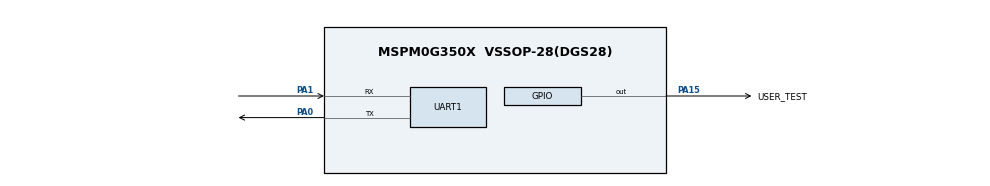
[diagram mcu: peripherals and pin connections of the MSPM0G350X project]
/**
 * @cliArgs --device "MSPM0G350X" --package "VSSOP-28(DGS28)" --part "Default" --product "mspm0_sdk@1.30.00.03"
 * @versions {"tool":"1.19.0+3426"}
 */

/**
 * Import the modules used in this configuration.
 */
const GPIO          = scripting.addModule("/ti/driverlib/GPIO", {}, false);
const GPIO1         = GPIO.addInstance();
const SYSCTL        = scripting.addModule("/ti/driverlib/SYSCTL");
const TIMER         = scripting.addModule("/ti/driverlib/TIMER", {}, false);
const TIMER1        = TIMER.addInstance();
const UART          = scripting.addModule("/ti/driverlib/UART", {}, false);
const UART1         = UART.addInstance();
const ProjectConfig = scripting.addModule("/ti/project_config/ProjectConfig");

/**
 * Write custom configuration values to the imported modules.
 */
const divider6       = system.clockTree["PLL_CLK2X_DIV"];
divider6.divideValue = 4;

const divider7       = system.clockTree["PLL_PDIV"];
divider7.divideValue = 2;

const divider9       = system.clockTree["UDIV"];
divider9.divideValue = 2;

const multiplier2         = system.clockTree["PLL_QDIV"];
multiplier2.multiplyValue = 10;

const mux8       = system.clockTree["HSCLKMUX"];
mux8.inputSelect = "HSCLKMUX_SYSPLL2X";

GPIO1.$name                         = "GPIO_LEDS";
GPIO1.port                          = "PORTA";
GPIO1.associatedPins[0].$name       = "USER_TEST";
GPIO1.associatedPins[0].pin.$assign = "PA15";

const Board = scripting.addModule("/ti/driverlib/Board", {}, false);

SYSCTL.forceDefaultClkConfig = true;
SYSCTL.clockTreeEn           = true;

TIMER1.timerStartTimer  = true;
TIMER1.$name            = "SWTIMER";
TIMER1.timerClkDiv      = 8;
TIMER1.timerPeriod      = "1.0";
TIMER1.timerClkPrescale = 256;
TIMER1.timerMode        = "PERIODIC";

UART1.$name                            = "DEBUG_SCI";
UART1.targetBaudRate                   = 115200;
UART1.parity                           = "EVEN";
UART1.enableFIFO                       = true;
UART1.peripheral.$assign               = "UART0";
UART1.peripheral.rxPin.$assign         = "PA1";
UART1.peripheral.txPin.$assign         = "PA0";
UART1.txPinConfig.$name                = "ti_driverlib_gpio_GPIOPinGeneric0";
UART1.txPinConfig.direction            = scripting.forceWrite("OUTPUT");
UART1.txPinConfig.hideOutputInversion  = scripting.forceWrite(false);
UART1.txPinConfig.onlyInternalResistor = scripting.forceWrite(false);
UART1.txPinConfig.passedPeripheralType = scripting.forceWrite("Digital");
UART1.rxPinConfig.$name                = "ti_driverlib_gpio_GPIOPinGeneric1";
UART1.rxPinConfig.hideOutputInversion  = scripting.forceWrite(false);
UART1.rxPinConfig.onlyInternalResistor = scripting.forceWrite(false);
UART1.rxPinConfig.passedPeripheralType = scripting.forceWrite("Digital");

ProjectConfig.deviceSpin = "MSPM0G3507";
scripting.suppress("Migrating requires going through the Switch Board or Device menu in the Device View section\\.", ProjectConfig, "deviceSpin");

/**
 * Pinmux solution for unlocked pins/peripherals. This ensures that minor changes to the automatic solver in a future
 * version of the tool will not impact the pinmux you originally saw.  These lines can be completely deleted in order to
 * re-solve from scratch.
 */
Board.peripheral.$suggestSolution          = "DEBUGSS";
Board.peripheral.swclkPin.$suggestSolution = "PA20";
Board.peripheral.swdioPin.$suggestSolution = "PA19";
TIMER1.peripheral.$suggestSolution         = "TIMA0";
